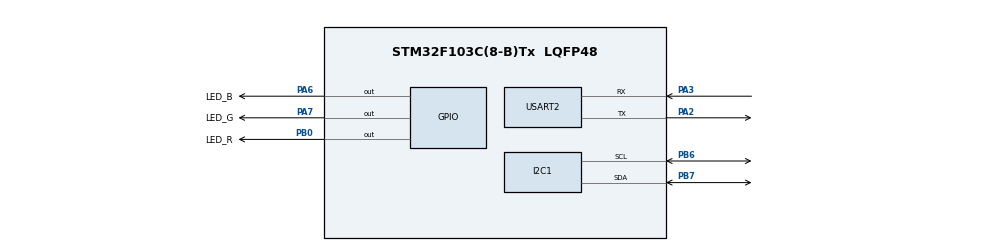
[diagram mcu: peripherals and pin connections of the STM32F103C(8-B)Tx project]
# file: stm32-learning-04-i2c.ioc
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Dma.I2C1_RX.0.Direction=DMA_PERIPH_TO_MEMORY
Dma.I2C1_RX.0.Instance=DMA1_Channel7
Dma.I2C1_RX.0.MemDataAlignment=DMA_MDATAALIGN_BYTE
Dma.I2C1_RX.0.MemInc=DMA_MINC_ENABLE
Dma.I2C1_RX.0.Mode=DMA_NORMAL
Dma.I2C1_RX.0.PeriphDataAlignment=DMA_PDATAALIGN_BYTE
Dma.I2C1_RX.0.PeriphInc=DMA_PINC_DISABLE
Dma.I2C1_RX.0.Priority=DMA_PRIORITY_LOW
Dma.I2C1_TX.1.Direction=DMA_MEMORY_TO_PERIPH
Dma.I2C1_TX.1.Instance=DMA1_Channel6
Dma.I2C1_TX.1.MemDataAlignment=DMA_MDATAALIGN_BYTE
Dma.I2C1_TX.1.MemInc=DMA_MINC_ENABLE
Dma.I2C1_TX.1.Mode=DMA_NORMAL
Dma.I2C1_TX.1.PeriphDataAlignment=DMA_PDATAALIGN_BYTE
Dma.I2C1_TX.1.PeriphInc=DMA_PINC_DISABLE
Dma.I2C1_TX.1.Priority=DMA_PRIORITY_LOW
Dma.Request0=I2C1_RX
Dma.Request1=I2C1_TX
Mcu.Family=STM32F1
Mcu.Name=STM32F103C(8-B)Tx
Mcu.Package=LQFP48
NVIC.DMA1_Channel6_IRQn=true\:0\:0\:false\:false\:true\:false\:true\:true
NVIC.DMA1_Channel7_IRQn=true\:0\:0\:false\:false\:true\:false\:true\:true
NVIC.I2C1_ER_IRQn=true\:0\:0\:false\:false\:true\:true\:true\:true
NVIC.I2C1_EV_IRQn=true\:0\:0\:true\:false\:true\:true\:true\:true
NVIC.PriorityGroup=NVIC_PRIORITYGROUP_4
NVIC.USART2_IRQn=true\:0\:0\:false\:false\:true\:true\:true\:true
PA13.Mode=Serial_Wire
PA13.Signal=SYS_JTMS-SWDIO
PA14.Mode=Serial_Wire
PA14.Signal=SYS_JTCK-SWCLK
PA2.Mode=Asynchronous
PA2.Signal=USART2_TX
PA3.Mode=Asynchronous
PA3.Signal=USART2_RX
PA6.GPIO_Label=LED_B
PA6.Signal=GPIO_Output
PA7.GPIO_Label=LED_G
PA7.Signal=GPIO_Output
PB0.GPIO_Label=LED_R
PB0.Signal=GPIO_Output
PB6.Mode=I2C
PB6.Signal=I2C1_SCL
PB7.Mode=I2C
PB7.Signal=I2C1_SDA
ProjectManager.HeapSize=0x200
ProjectManager.StackSize=0x400
ProjectManager.TargetToolchain=CMake
RCC.APB1Freq_Value=8000000
RCC.APB2Freq_Value=8000000
USART2.VirtualMode=VM_ASYNC
board=custom

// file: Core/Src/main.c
/* USER CODE BEGIN Header */
/**
 ******************************************************************************
 * @file           : main.c
 * @brief          : Main program body
 ******************************************************************************
 * @attention
 *
 * Copyright (c) 2026 STMicroelectronics.
 * All rights reserved.
 *
 * This software is licensed under terms that can be found in the LICENSE file
 * in the root directory of this software component.
 * If no LICENSE file comes with this software, it is provided AS-IS.
 *
 ******************************************************************************
 */
/* USER CODE END Header */
#include "main.h"
#include "dma.h"
#include "i2c.h"
#include "usart.h"
#include "gpio.h"

/* USER CODE BEGIN Includes */

#include "app_main.hpp"

/* USER CODE END Includes */

void SystemClock_Config(void);

int main(void)
{

  /* MCU Configuration--------------------------------------------------------*/

  /* Reset of all peripherals, Initializes the Flash interface and the Systick. */
  HAL_Init();

  /* Configure the system clock */
  SystemClock_Config();

  /* Initialize all configured peripherals */
  MX_GPIO_Init();
  MX_DMA_Init();
  MX_I2C1_Init();
  MX_USART2_UART_Init();
  /* USER CODE BEGIN 2 */

  cpp_setup();

  /* USER CODE END 2 */

  /* Infinite loop */
  /* USER CODE BEGIN WHILE */
  while (1) {

    cpp_loop();

    /* USER CODE END WHILE */

  }
}

void SystemClock_Config(void)
{
  RCC_OscInitTypeDef RCC_OscInitStruct = {0};
  RCC_ClkInitTypeDef RCC_ClkInitStruct = {0};

  /** Initializes the RCC Oscillators according to the specified parameters
  * in the RCC_OscInitTypeDef structure.
  */
  RCC_OscInitStruct.OscillatorType = RCC_OSCILLATORTYPE_HSI;
  RCC_OscInitStruct.HSIState = RCC_HSI_ON;
  RCC_OscInitStruct.HSICalibrationValue = RCC_HSICALIBRATION_DEFAULT;
  RCC_OscInitStruct.PLL.PLLState = RCC_PLL_NONE;
  if (HAL_RCC_OscConfig(&RCC_OscInitStruct) != HAL_OK)
  {
    Error_Handler();
  }

  /** Initializes the CPU, AHB and APB buses clocks
  */
  RCC_ClkInitStruct.ClockType = RCC_CLOCKTYPE_HCLK|RCC_CLOCKTYPE_SYSCLK
                              |RCC_CLOCKTYPE_PCLK1|RCC_CLOCKTYPE_PCLK2;
  RCC_ClkInitStruct.SYSCLKSource = RCC_SYSCLKSOURCE_HSI;
  RCC_ClkInitStruct.AHBCLKDivider = RCC_SYSCLK_DIV1;
  RCC_ClkInitStruct.APB1CLKDivider = RCC_HCLK_DIV1;
  RCC_ClkInitStruct.APB2CLKDivider = RCC_HCLK_DIV1;

  if (HAL_RCC_ClockConfig(&RCC_ClkInitStruct, FLASH_LATENCY_0) != HAL_OK)
  {
    Error_Handler();
  }
}

void Error_Handler(void)
{
  __disable_irq();
  while (1) {
  }
}
#ifdef USE_FULL_ASSERT
/**
  * @brief  Reports the name of the source file and the source line number
  *         where the assert_param error has occurred.
  * @param  file: pointer to the source file name
  * @param  line: assert_param error line source number
  * @retval None
  */
void assert_failed(uint8_t *file, uint32_t line)
{
  /* USER CODE BEGIN 6 */
  /* User can add his own implementation to report the file name and line
     number, ex: printf("Wrong parameters value: file %s on line %d\r\n", file,
     line) */
  /* USER CODE END 6 */
}
#endif /* USE_FULL_ASSERT */
